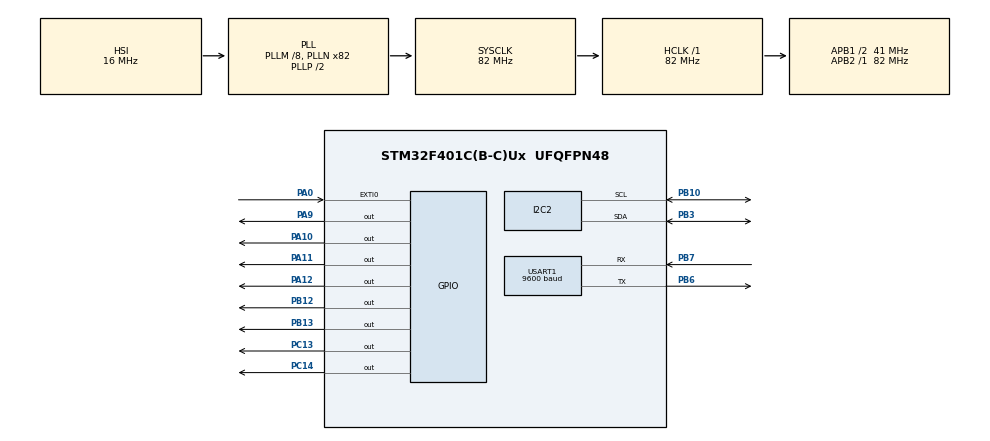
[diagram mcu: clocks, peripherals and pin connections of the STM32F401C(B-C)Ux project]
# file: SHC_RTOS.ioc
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FREERTOS.Tasks01=defaultTask,24,128,StartDefaultTask,Default,NULL,Dynamic,NULL,NULL
Mcu.Family=STM32F4
Mcu.Name=STM32F401C(B-C)Ux
Mcu.Package=UFQFPN48
NVIC.EXTI0_IRQn=true\:5\:0\:false\:false\:true\:true\:true\:true\:true
NVIC.PriorityGroup=NVIC_PRIORITYGROUP_4
NVIC.TIM2_IRQn=true\:15\:0\:false\:false\:true\:false\:false\:true\:true
NVIC.TimeBase=TIM2_IRQn
NVIC.TimeBaseIP=TIM2
PA0-WKUP.GPIO_ModeDefaultEXTI=GPIO_MODE_IT_FALLING
PA0-WKUP.GPIO_PuPd=GPIO_PULLUP
PA0-WKUP.Signal=GPXTI0
PA10.Signal=GPIO_Output
PA11.Signal=GPIO_Output
PA12.Signal=GPIO_Output
PA13.Mode=Serial_Wire
PA13.Signal=SYS_JTMS-SWDIO
PA14.Mode=Serial_Wire
PA14.Signal=SYS_JTCK-SWCLK
PA9.Signal=GPIO_Output
PB10.Mode=I2C
PB10.Signal=I2C2_SCL
PB12.Signal=GPIO_Output
PB13.Signal=GPIO_Output
PB3.Mode=I2C
PB3.Signal=I2C2_SDA
PB6.Mode=Asynchronous
PB6.Signal=USART1_TX
PB7.Mode=Asynchronous
PB7.Signal=USART1_RX
PC13-ANTI_TAMP.Signal=GPIO_Output
PC14-OSC32_IN.Signal=GPIO_Output
ProjectManager.HeapSize=0x200
ProjectManager.StackSize=0x400
ProjectManager.TargetToolchain=STM32CubeIDE
RCC.48MHZClocksFreq_Value=41000000
RCC.AHBFreq_Value=82000000
RCC.APB1CLKDivider=RCC_HCLK_DIV2
RCC.APB1Freq_Value=41000000
RCC.APB1TimFreq_Value=82000000
RCC.APB2Freq_Value=82000000
RCC.APB2TimFreq_Value=82000000
RCC.CortexFreq_Value=82000000
RCC.HCLKFreq_Value=82000000
RCC.HSE_VALUE=25000000
RCC.HSI_VALUE=16000000
RCC.LSE_VALUE=32768
RCC.PLLM=8
RCC.PLLN=82
RCC.SYSCLKFreq_VALUE=82000000
RCC.SYSCLKSource=RCC_SYSCLKSOURCE_PLLCLK
RCC.VCOOutputFreq_Value=164000000
USART1.BaudRate=9600
USART1.VirtualMode=VM_ASYNC
VP_FREERTOS_VS_CMSIS_V2.Mode=CMSIS_V2
VP_SYS_VS_tim2.Mode=TIM2
board=custom

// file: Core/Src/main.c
/* USER CODE BEGIN Header */
/**
  ******************************************************************************
  * @file           : main.c
  * @brief          : Main program body
  ******************************************************************************
  * @attention
  *
  * Copyright (c) 2026 STMicroelectronics.
  * All rights reserved.
  *
  * This software is licensed under terms that can be found in the LICENSE file
  * in the root directory of this software component.
  * If no LICENSE file comes with this software, it is provided AS-IS.
  *
  ******************************************************************************
  */
/* USER CODE END Header */
#include "main.h"
#include "cmsis_os.h"

/* USER CODE BEGIN Includes */
#include "FreeRTOS.h"
#include "queue.h"
#include <stdio.h>
#include "timers.h"
#include "event_groups.h"
#include "semphr.h"
#include <string.h>
#include <string.h>
/* USER CODE END Includes */

I2C_HandleTypeDef hi2c2;

UART_HandleTypeDef huart1;

/* Definitions for defaultTask */
osThreadId_t defaultTaskHandle;
const osThreadAttr_t defaultTask_attributes = {
  .name = "defaultTask",
  .stack_size = 128 * 4,
  .priority = (osPriority_t) osPriorityNormal,
};

void SystemClock_Config(void);
static void MX_GPIO_Init(void);
static void MX_I2C2_Init(void);
static void MX_USART1_UART_Init(void);
void StartDefaultTask(void *argument);

/* USER CODE BEGIN PFP */
UBaseType_t freeStack;
UBaseType_t freeheap;

xTaskHandle ptemph;
xTaskHandle clcdh;
xTaskHandle motionint;
xTaskHandle event;
xTaskHandle logh;

EventGroupHandle_t eventh;
uint8_t buffer[2];
uint16_t temp;
xQueueHandle queueh;
char copy[20];
xTimerHandle stim;
SemaphoreHandle_t mutexh;
char arr[] = "system active!!\r\n";
uint8_t data = 0x00;
UBaseType_t freestack;
/* USER CODE END PFP */

/* USER CODE BEGIN 0 */
uint16_t mpu_read();
void ptemp(void *argument);
void clcd(void *argument);
void Enable_Pulse(void);
void LCD_SendInitNibble(uint8_t nibble);
void Send_Nibble(uint8_t nibble);
void Lcd_Sendbyte(uint8_t data);
void Lcd_Command(uint8_t cmd);void Lcd_Data(uint8_t data);
void Lcd_Init(void);
void Lcd_Data(uint8_t data);
void Lcd_Clear(void);
void Lcd_Home(void);
void Lcd_Setcursor(uint8_t row, uint8_t col);
void Lcd_Print(char *str);
void motion_int(void *argument);
void motionintcallback();
void EGtask(void *argument);
UBaseType_t uxTaskGetStackHighWaterMark( TaskHandle_t xTask );
void MPU6050_Init(void);
void logtask(void *argument);

/* USER CODE END 0 */

int main(void)
{

  /* MCU Configuration--------------------------------------------------------*/

  /* Reset of all peripherals, Initializes the Flash interface and the Systick. */
  HAL_Init();

  /* Configure the system clock */
  SystemClock_Config();

  /* Initialize all configured peripherals */
  MX_GPIO_Init();
  MX_I2C2_Init();
  MX_USART1_UART_Init();
  /* USER CODE BEGIN 2 */
  Lcd_Init();
  MPU6050_Init();

  /* USER CODE END 2 */

  /* Init scheduler */
  osKernelInitialize();

  /* Create the thread(s) */
  /* creation of defaultTask */
  defaultTaskHandle = osThreadNew(StartDefaultTask, NULL, &defaultTask_attributes);

  /* USER CODE BEGIN RTOS_THREADS */
  /* add threads, ... */
    xTaskCreate(ptemp,"producertemp" , 128, NULL, 2, &ptemph);
    xTaskCreate(clcd,"consumerlcd" , 128, NULL, 10, &clcdh);
    xTaskCreate(motion_int,"motioninterrupt" , 128, NULL, 3, &motionint);
    xTaskCreate(EGtask, "event", 128, NULL, 1, &event);
    xTaskCreate(logtask, "log", 128, NULL, 1, &logh);

    stim = xTimerCreate("motiontimer",5000,pdTRUE,NULL,motionintcallback);
    queueh = xQueueCreate( 5, sizeof(uint16_t));
    eventh = xEventGroupCreate();
    mutexh = xSemaphoreCreateMutex();
    xTimerStart(stim,0);

  /* USER CODE END RTOS_THREADS */

  /* Start scheduler */
  osKernelStart();

  /* We should never get here as control is now taken by the scheduler */

  /* Infinite loop */
  while (1)
  {

  }
}

void SystemClock_Config(void)
{
  RCC_OscInitTypeDef RCC_OscInitStruct = {0};
  RCC_ClkInitTypeDef RCC_ClkInitStruct = {0};

  /** Configure the main internal regulator output voltage
  */
  __HAL_RCC_PWR_CLK_ENABLE();
  __HAL_PWR_VOLTAGESCALING_CONFIG(PWR_REGULATOR_VOLTAGE_SCALE2);

  /** Initializes the RCC Oscillators according to the specified parameters
  * in the RCC_OscInitTypeDef structure.
  */
  RCC_OscInitStruct.OscillatorType = RCC_OSCILLATORTYPE_HSI;
  RCC_OscInitStruct.HSIState = RCC_HSI_ON;
  RCC_OscInitStruct.HSICalibrationValue = RCC_HSICALIBRATION_DEFAULT;
  RCC_OscInitStruct.PLL.PLLState = RCC_PLL_ON;
  RCC_OscInitStruct.PLL.PLLSource = RCC_PLLSOURCE_HSI;
  RCC_OscInitStruct.PLL.PLLM = 8;
  RCC_OscInitStruct.PLL.PLLN = 82;
  RCC_OscInitStruct.PLL.PLLP = RCC_PLLP_DIV2;
  RCC_OscInitStruct.PLL.PLLQ = 4;
  if (HAL_RCC_OscConfig(&RCC_OscInitStruct) != HAL_OK)
  {
    Error_Handler();
  }

  /** Initializes the CPU, AHB and APB buses clocks
  */
  RCC_ClkInitStruct.ClockType = RCC_CLOCKTYPE_HCLK|RCC_CLOCKTYPE_SYSCLK
                              |RCC_CLOCKTYPE_PCLK1|RCC_CLOCKTYPE_PCLK2;
  RCC_ClkInitStruct.SYSCLKSource = RCC_SYSCLKSOURCE_PLLCLK;
  RCC_ClkInitStruct.AHBCLKDivider = RCC_SYSCLK_DIV1;
  RCC_ClkInitStruct.APB1CLKDivider = RCC_HCLK_DIV2;
  RCC_ClkInitStruct.APB2CLKDivider = RCC_HCLK_DIV1;

  if (HAL_RCC_ClockConfig(&RCC_ClkInitStruct, FLASH_LATENCY_2) != HAL_OK)
  {
    Error_Handler();
  }
}

static void MX_I2C2_Init(void)
{

  hi2c2.Instance = I2C2;
  hi2c2.Init.ClockSpeed = 100000;
  hi2c2.Init.DutyCycle = I2C_DUTYCYCLE_2;
  hi2c2.Init.OwnAddress1 = 0;
  hi2c2.Init.AddressingMode = I2C_ADDRESSINGMODE_7BIT;
  hi2c2.Init.DualAddressMode = I2C_DUALADDRESS_DISABLE;
  hi2c2.Init.OwnAddress2 = 0;
  hi2c2.Init.GeneralCallMode = I2C_GENERALCALL_DISABLE;
  hi2c2.Init.NoStretchMode = I2C_NOSTRETCH_DISABLE;
  if (HAL_I2C_Init(&hi2c2) != HAL_OK)
  {
    Error_Handler();
  }

}

static void MX_USART1_UART_Init(void)
{

  huart1.Instance = USART1;
  huart1.Init.BaudRate = 9600;
  huart1.Init.WordLength = UART_WORDLENGTH_8B;
  huart1.Init.StopBits = UART_STOPBITS_1;
  huart1.Init.Parity = UART_PARITY_NONE;
  huart1.Init.Mode = UART_MODE_TX_RX;
  huart1.Init.HwFlowCtl = UART_HWCONTROL_NONE;
  huart1.Init.OverSampling = UART_OVERSAMPLING_16;
  if (HAL_UART_Init(&huart1) != HAL_OK)
  {
    Error_Handler();
  }

}

static void MX_GPIO_Init(void)
{
  GPIO_InitTypeDef GPIO_InitStruct = {0};

  /* GPIO Ports Clock Enable */
  __HAL_RCC_GPIOC_CLK_ENABLE();
  __HAL_RCC_GPIOA_CLK_ENABLE();
  __HAL_RCC_GPIOB_CLK_ENABLE();

  /*Configure GPIO pin Output Level */
  HAL_GPIO_WritePin(GPIOC, GPIO_PIN_13|GPIO_PIN_14, GPIO_PIN_RESET);

  /*Configure GPIO pin Output Level */
  HAL_GPIO_WritePin(GPIOB, GPIO_PIN_12|GPIO_PIN_13, GPIO_PIN_RESET);

  /*Configure GPIO pin Output Level */
  HAL_GPIO_WritePin(GPIOA, GPIO_PIN_9|GPIO_PIN_10|GPIO_PIN_11|GPIO_PIN_12, GPIO_PIN_RESET);

  /*Configure GPIO pins : PC13 PC14 */
  GPIO_InitStruct.Pin = GPIO_PIN_13|GPIO_PIN_14;
  GPIO_InitStruct.Mode = GPIO_MODE_OUTPUT_PP;
  GPIO_InitStruct.Pull = GPIO_NOPULL;
  GPIO_InitStruct.Speed = GPIO_SPEED_FREQ_LOW;
  HAL_GPIO_Init(GPIOC, &GPIO_InitStruct);

  /*Configure GPIO pin : PA0 */
  GPIO_InitStruct.Pin = GPIO_PIN_0;
  GPIO_InitStruct.Mode = GPIO_MODE_IT_FALLING;
  GPIO_InitStruct.Pull = GPIO_PULLUP;
  HAL_GPIO_Init(GPIOA, &GPIO_InitStruct);

  /*Configure GPIO pins : PB12 PB13 */
  GPIO_InitStruct.Pin = GPIO_PIN_12|GPIO_PIN_13;
  GPIO_InitStruct.Mode = GPIO_MODE_OUTPUT_PP;
  GPIO_InitStruct.Pull = GPIO_NOPULL;
  GPIO_InitStruct.Speed = GPIO_SPEED_FREQ_LOW;
  HAL_GPIO_Init(GPIOB, &GPIO_InitStruct);

  /*Configure GPIO pins : PA9 PA10 PA11 PA12 */
  GPIO_InitStruct.Pin = GPIO_PIN_9|GPIO_PIN_10|GPIO_PIN_11|GPIO_PIN_12;
  GPIO_InitStruct.Mode = GPIO_MODE_OUTPUT_PP;
  GPIO_InitStruct.Pull = GPIO_NOPULL;
  GPIO_InitStruct.Speed = GPIO_SPEED_FREQ_LOW;
  HAL_GPIO_Init(GPIOA, &GPIO_InitStruct);

  GPIO_InitStruct.Pin = GPIO_PIN_1;
  GPIO_InitStruct.Mode = GPIO_MODE_IT_FALLING;
  GPIO_InitStruct.Pull = GPIO_PULLUP;
  HAL_GPIO_Init(GPIOA, &GPIO_InitStruct);

  /* EXTI interrupt init*/
  HAL_NVIC_SetPriority(EXTI0_IRQn, 5, 0);
  HAL_NVIC_EnableIRQ(EXTI0_IRQn);

  HAL_NVIC_SetPriority(EXTI1_IRQn, 5, 0);
    HAL_NVIC_EnableIRQ(EXTI1_IRQn);

}

/* USER CODE BEGIN 4 */
void ptemp(void *argument){
	uint16_t localtemp;
	while(1){
		localtemp = mpu_read();

		xQueueSend(queueh,
		&localtemp,
		1000);
		  freestack = uxTaskGetStackHighWaterMark(NULL);

		vTaskDelay(1000);

	}

}

void clcd(void *argument){
	uint16_t buf;
	while(1){
		xQueueReceive(queueh,
		&buf,
		portMAX_DELAY);
		sprintf(copy, "temp: %u", buf);
		Lcd_Setcursor(0, 0);
		Lcd_Print(copy);

	}

}

void motion_int(void *argument){

	while(1){
	ulTaskNotifyTake(pdTRUE, portMAX_DELAY);
	HAL_GPIO_WritePin(GPIOC, GPIO_PIN_13, GPIO_PIN_RESET);
	xTimerReset(stim,0);

}
}

void EGtask(void *argument){

while(1){

	xEventGroupWaitBits(eventh,
	 1<<0,
	 pdTRUE,
	pdFALSE,
	portMAX_DELAY);
	HAL_GPIO_TogglePin(GPIOC, GPIO_PIN_14);

}
}

void motionintcallback(){

	HAL_GPIO_WritePin(GPIOC, GPIO_PIN_13, GPIO_PIN_SET);

}

void HAL_GPIO_EXTI_Callback(uint16_t GPIO_Pin)
{ if(GPIO_Pin == GPIO_PIN_0){
  BaseType_t var = pdFALSE;

  vTaskNotifyGiveFromISR(motionint,&var);

  portYIELD_FROM_ISR(var);}

if(GPIO_Pin == GPIO_PIN_1){
	BaseType_t var = pdFALSE;
    xEventGroupSetBitsFromISR(eventh,1<<0,&var);
	  portYIELD_FROM_ISR(var);
}

}

void logtask(void *argument){

while(1){
	xSemaphoreTake(mutexh, portMAX_DELAY);

	HAL_UART_Transmit(&huart1, (uint8_t*)arr, strlen(arr), 1000);

	xSemaphoreGive(mutexh);

     vTaskDelay(500);

     freestack = uxTaskGetStackHighWaterMark(NULL);
}

}
uint16_t mpu_read(){
	HAL_I2C_Mem_Read(&hi2c2, 0x68<<1, 0x41, 1, 	(uint8_t*)buffer, 2, 1000);
	temp = (buffer[0]<<8)|buffer[1];
	return temp;
}

void Enable_Pulse(void)
{
    HAL_GPIO_WritePin(GPIOB, GPIO_PIN_13, GPIO_PIN_SET);
    HAL_Delay(1);
    HAL_GPIO_WritePin(GPIOB, GPIO_PIN_13, GPIO_PIN_RESET);
    HAL_Delay(1);
}
void LCD_SendInitNibble(uint8_t nibble)
{
    HAL_GPIO_WritePin(GPIOA, GPIO_PIN_12, (nibble & 0x01) ? GPIO_PIN_SET : GPIO_PIN_RESET);
    HAL_GPIO_WritePin(GPIOA, GPIO_PIN_11, (nibble & 0x02) ? GPIO_PIN_SET : GPIO_PIN_RESET);
    HAL_GPIO_WritePin(GPIOA, GPIO_PIN_10, (nibble & 0x04) ? GPIO_PIN_SET : GPIO_PIN_RESET);
    HAL_GPIO_WritePin(GPIOA, GPIO_PIN_9, (nibble & 0x08) ? GPIO_PIN_SET : GPIO_PIN_RESET);

    Enable_Pulse();
}
void Send_Nibble(uint8_t nibble)
{
    HAL_GPIO_WritePin(GPIOA, GPIO_PIN_12, (nibble & 0x01) ? GPIO_PIN_SET : GPIO_PIN_RESET);
    HAL_GPIO_WritePin(GPIOA, GPIO_PIN_11, (nibble & 0x02) ? GPIO_PIN_SET : GPIO_PIN_RESET);
    HAL_GPIO_WritePin(GPIOA, GPIO_PIN_10, (nibble & 0x04) ? GPIO_PIN_SET : GPIO_PIN_RESET);
    HAL_GPIO_WritePin(GPIOA, GPIO_PIN_9, (nibble & 0x08) ? GPIO_PIN_SET : GPIO_PIN_RESET);

    Enable_Pulse();
}
void Lcd_Sendbyte(uint8_t data)
{
    Send_Nibble(data >> 4);
    Send_Nibble(data & 0x0F);
}
void Lcd_Command(uint8_t cmd)
{
    HAL_GPIO_WritePin(GPIOB, GPIO_PIN_12, GPIO_PIN_RESET);

    Lcd_Sendbyte(cmd);

    HAL_Delay(2);
}
void Lcd_Data(uint8_t data)
{
    HAL_GPIO_WritePin(GPIOB, GPIO_PIN_12, GPIO_PIN_SET);

    Lcd_Sendbyte(data);

    HAL_Delay(1);
}
void Lcd_Init(void)
{
    HAL_GPIO_WritePin(GPIOB, GPIO_PIN_12, GPIO_PIN_RESET);

    HAL_Delay(20);

    LCD_SendInitNibble(0x03);
    HAL_Delay(5);

    LCD_SendInitNibble(0x03);
    HAL_Delay(1);

    LCD_SendInitNibble(0x03);
    HAL_Delay(1);

    LCD_SendInitNibble(0x02);
    HAL_Delay(1);

    Lcd_Command(0x28);      // 4-bit, 2-line, 5x8
    Lcd_Command(0x08);      // Display OFF
    Lcd_Command(0x01);      // Clear Display
    HAL_Delay(2);
    Lcd_Command(0x06);      // Entry mode
    Lcd_Command(0x0C);      // Display ON, Cursor OFF
}
void Lcd_Clear(void)
{
    Lcd_Command(0x01);
}
void Lcd_Home(void)
{
    Lcd_Command(0x02);
}
void Lcd_Setcursor(uint8_t row, uint8_t col)
{
    uint8_t addr;

    if(row == 0)
        addr = 0x80 + col;
    else
        addr = 0xC0 + col;

    Lcd_Command(addr);
}
void Lcd_Print(char *str)
{
    while(*str)
    {
        Lcd_Data(*str++);
    }
}

void MPU6050_Init(void)
{
    // Wake up
    HAL_I2C_Mem_Write(&hi2c2,
                      0x68 << 1,
                      0x6B,
                      I2C_MEMADD_SIZE_8BIT,
                      &data,
                      1,
                      1000);
}
/* USER CODE END 4 */

void StartDefaultTask(void *argument)
{
  for(;;)
  {
    osDelay(1);
  }
}

void HAL_TIM_PeriodElapsedCallback(TIM_HandleTypeDef *htim)
{
  if (htim->Instance == TIM2)
  {
    HAL_IncTick();
  }
}

void Error_Handler(void)
{
  __disable_irq();
  while (1)
  {
  }
}
